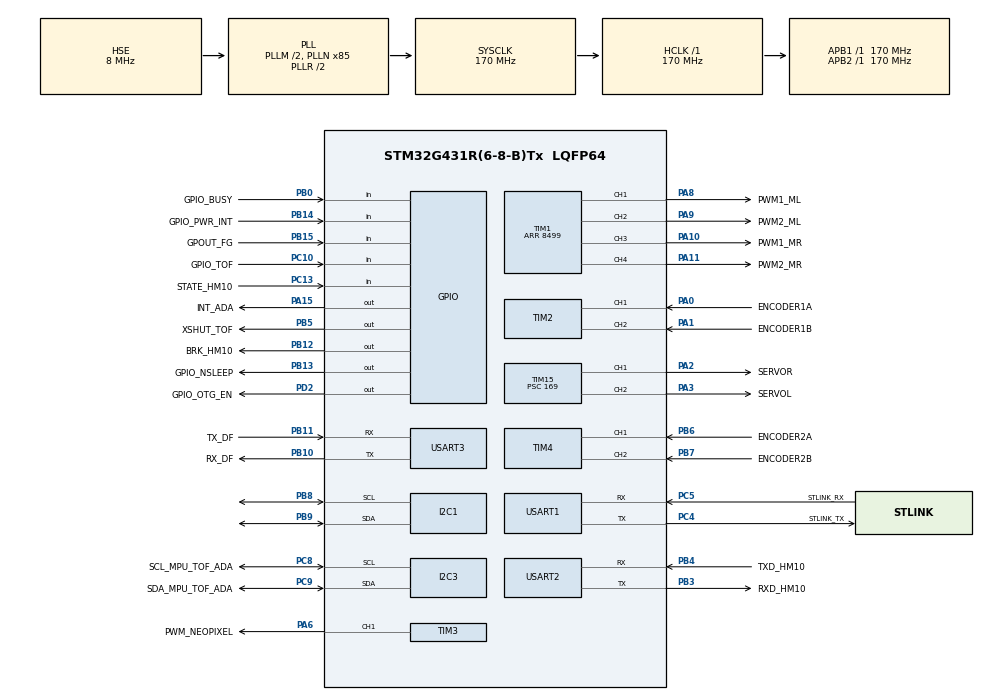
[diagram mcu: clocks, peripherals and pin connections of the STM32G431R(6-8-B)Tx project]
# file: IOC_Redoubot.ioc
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Dma.Request0=TIM3_CH1
Dma.TIM3_CH1.0.Direction=DMA_MEMORY_TO_PERIPH
Dma.TIM3_CH1.0.EventEnable=DISABLE
Dma.TIM3_CH1.0.Instance=DMA1_Channel1
Dma.TIM3_CH1.0.MemDataAlignment=DMA_MDATAALIGN_WORD
Dma.TIM3_CH1.0.MemInc=DMA_MINC_ENABLE
Dma.TIM3_CH1.0.Mode=DMA_NORMAL
Dma.TIM3_CH1.0.PeriphDataAlignment=DMA_PDATAALIGN_HALFWORD
Dma.TIM3_CH1.0.PeriphInc=DMA_PINC_DISABLE
Dma.TIM3_CH1.0.Polarity=HAL_DMAMUX_REQ_GEN_RISING
Dma.TIM3_CH1.0.Priority=DMA_PRIORITY_HIGH
Dma.TIM3_CH1.0.RequestNumber=1
Dma.TIM3_CH1.0.SignalID=NONE
Dma.TIM3_CH1.0.SyncEnable=DISABLE
Dma.TIM3_CH1.0.SyncPolarity=HAL_DMAMUX_SYNC_NO_EVENT
Dma.TIM3_CH1.0.SyncRequestNumber=1
Dma.TIM3_CH1.0.SyncSignalID=NONE
I2C1.Timing=0x40B285C2
I2C3.Timing=0x40B285C2
Mcu.Family=STM32G4
Mcu.Name=STM32G431R(6-8-B)Tx
Mcu.Package=LQFP64
NVIC.DMA1_Channel1_IRQn=true\:0\:0\:false\:false\:true\:false\:true\:true
NVIC.PriorityGroup=NVIC_PRIORITYGROUP_4
PA0.GPIO_Label=ENCODER1A
PA0.Signal=S_TIM2_CH1
PA1.GPIO_Label=ENCODER1B
PA1.Signal=S_TIM2_CH2
PA10.GPIO_Label=PWM1_MR
PA10.Signal=S_TIM1_CH3
PA11.GPIO_Label=PWM2_MR
PA11.Signal=S_TIM1_CH4
PA13.Mode=Serial_Wire
PA13.Signal=SYS_JTMS-SWDIO
PA14.Mode=Serial_Wire
PA14.Signal=SYS_JTCK-SWCLK
PA15.GPIO_Label=INT_ADA
PA15.Signal=GPIO_Output
PA2.GPIO_Label=SERVOR
PA2.Signal=S_TIM15_CH1
PA3.GPIO_Label=SERVOL
PA3.Signal=S_TIM15_CH2
PA6.GPIO_Label=PWM_NEOPIXEL
PA6.GPIO_Speed=GPIO_SPEED_FREQ_VERY_HIGH
PA6.Signal=S_TIM3_CH1
PA8.GPIO_Label=PWM1_ML
PA8.Signal=S_TIM1_CH1
PA9.GPIO_Label=PWM2_ML
PA9.Signal=S_TIM1_CH2
PB0.GPIO_Label=GPIO_BUSY
PB0.Signal=GPIO_Input
PB10.GPIO_Label=RX_DF
PB10.Mode=Asynchronous
PB10.Signal=USART3_TX
PB11.GPIO_Label=TX_DF
PB11.Mode=Asynchronous
PB11.Signal=USART3_RX
PB12.GPIO_Label=BRK_HM10
PB12.Signal=GPIO_Output
PB13.GPIO_Label=GPIO_NSLEEP
PB13.Signal=GPIO_Output
PB14.GPIO_Label=GPIO_PWR_INT
PB14.Signal=GPIO_Input
PB15.GPIO_Label=GPOUT_FG
PB15.Signal=GPIO_Input
PB3.GPIO_Label=RXD_HM10
PB3.Mode=Asynchronous
PB3.Signal=USART2_TX
PB4.GPIO_Label=TXD_HM10
PB4.Mode=Asynchronous
PB4.Signal=USART2_RX
PB5.GPIO_Label=XSHUT_TOF
PB5.Signal=GPIO_Output
PB6.GPIO_Label=ENCODER2A
PB6.Signal=S_TIM4_CH1
PB7.GPIO_Label=ENCODER2B
PB7.Signal=S_TIM4_CH2
PB8-BOOT0.Mode=I2C
PB8-BOOT0.Signal=I2C1_SCL
PB9.Mode=I2C
PB9.Signal=I2C1_SDA
PC10.GPIO_Label=GPIO_TOF
PC10.Signal=GPIO_Input
PC13.GPIO_Label=STATE_HM10
PC13.Signal=GPIO_Input
PC4.GPIO_Label=STLINK_TX
PC4.Mode=Asynchronous
PC4.Signal=USART1_TX
PC5.GPIO_Label=STLINK_RX
PC5.Mode=Asynchronous
PC5.Signal=USART1_RX
PC8.GPIO_Label=SCL_MPU_TOF_ADA
PC8.Mode=I2C
PC8.Signal=I2C3_SCL
PC9.GPIO_Label=SDA_MPU_TOF_ADA
PC9.Mode=I2C
PC9.Signal=I2C3_SDA
PD2.GPIO_Label=GPIO_OTG_EN
PD2.Signal=GPIO_Output
PF0-OSC_IN.Mode=HSE-External-Oscillator
PF0-OSC_IN.Signal=RCC_OSC_IN
PF1-OSC_OUT.Mode=HSE-External-Oscillator
PF1-OSC_OUT.Signal=RCC_OSC_OUT
ProjectManager.HeapSize=0x200
ProjectManager.StackSize=0x400
ProjectManager.TargetToolchain=CMake
RCC.ADC12Freq_Value=170000000
RCC.AHBFreq_Value=170000000
RCC.APB1Freq_Value=170000000
RCC.APB1TimFreq_Value=170000000
RCC.APB2Freq_Value=170000000
RCC.APB2TimFreq_Value=170000000
RCC.CK48CLockSelection=RCC_USBCLKSOURCE_HSI48
RCC.CortexFreq_Value=170000000
RCC.EXTERNAL_CLOCK_VALUE=12288000
RCC.HCLKFreq_Value=170000000
RCC.HSE_VALUE=8000000
RCC.HSI48_VALUE=48000000
RCC.HSI_VALUE=16000000
RCC.LSE_VALUE=32768
RCC.PLLM=RCC_PLLM_DIV2
RCC.PLLN=85
RCC.PLLQ=RCC_PLLQ_DIV4
RCC.PLLSourceVirtual=RCC_PLLSOURCE_HSE
RCC.SYSCLKFreq_VALUE=170000000
RCC.SYSCLKSource=RCC_SYSCLKSOURCE_PLLCLK
RCC.USBFreq_Value=48000000
RCC.VCOOutputFreq_Value=340000000
SH.S_TIM15_CH1.0=TIM15_CH1,PWM Generation1 CH1
SH.S_TIM15_CH2.0=TIM15_CH2,PWM Generation2 CH2
SH.S_TIM1_CH1.0=TIM1_CH1,PWM Generation1 CH1
SH.S_TIM1_CH2.0=TIM1_CH2,PWM Generation2 CH2
SH.S_TIM1_CH3.0=TIM1_CH3,PWM Generation3 CH3
SH.S_TIM1_CH4.0=TIM1_CH4,PWM Generation4 CH4
SH.S_TIM2_CH1.0=TIM2_CH1,Encoder_Interface
SH.S_TIM2_CH2.0=TIM2_CH2,Encoder_Interface
SH.S_TIM3_CH1.0=TIM3_CH1,PWM Generation1 CH1
SH.S_TIM4_CH1.0=TIM4_CH1,Encoder_Interface
SH.S_TIM4_CH2.0=TIM4_CH2,Encoder_Interface
TIM1.AutoReloadPreload=TIM_AUTORELOAD_PRELOAD_ENABLE
TIM1.Channel-PWM\ Generation1\ CH1=TIM_CHANNEL_1
TIM1.Channel-PWM\ Generation2\ CH2=TIM_CHANNEL_2
TIM1.Channel-PWM\ Generation3\ CH3=TIM_CHANNEL_3
TIM1.Channel-PWM\ Generation4\ CH4=TIM_CHANNEL_4
TIM1.PeriodNoDither=8499
TIM15.Channel-PWM\ Generation1\ CH1=TIM_CHANNEL_1
TIM15.Channel-PWM\ Generation2\ CH2=TIM_CHANNEL_2
TIM15.PeriodNoDither=19999
TIM15.Prescaler=169
TIM2.IC1Filter=4
TIM3.Channel-PWM\ Generation1\ CH1=TIM_CHANNEL_1
TIM3.PeriodNoDither=212
TIM3.Prescaler=0
TIM4.IC1Filter=4
USART1.VirtualMode-Asynchronous=VM_ASYNC
USART2.VirtualMode-Asynchronous=VM_ASYNC
USART3.VirtualMode-Asynchronous=VM_ASYNC
VP_SYS_VS_DBSignals.Mode=DisableDeadBatterySignals
board=custom

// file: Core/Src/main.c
/* USER CODE BEGIN Header */
/**
 ******************************************************************************
 * @file           : main.c
 * @brief          : Main program body
 ******************************************************************************
 * @attention
 *
 * Copyright (c) 2026 STMicroelectronics.
 * All rights reserved.
 *
 * This software is licensed under terms that can be found in the LICENSE file
 * in the root directory of this software component.
 * If no LICENSE file comes with this software, it is provided AS-IS.
 *
 ******************************************************************************
 */
/* USER CODE END Header */
#include "main.h"

/* USER CODE BEGIN Includes */
#include "neopixel.h"
/* USER CODE END Includes */

I2C_HandleTypeDef hi2c1;
I2C_HandleTypeDef hi2c3;

TIM_HandleTypeDef htim1;
TIM_HandleTypeDef htim2;
TIM_HandleTypeDef htim3;
TIM_HandleTypeDef htim4;
TIM_HandleTypeDef htim15;
DMA_HandleTypeDef hdma_tim3_ch1;

UART_HandleTypeDef huart1;
UART_HandleTypeDef huart2;
UART_HandleTypeDef huart3;

void SystemClock_Config(void);
static void MX_GPIO_Init(void);
static void MX_DMA_Init(void);
static void MX_I2C1_Init(void);
static void MX_I2C3_Init(void);
static void MX_TIM1_Init(void);
static void MX_TIM2_Init(void);
static void MX_TIM3_Init(void);
static void MX_USART2_UART_Init(void);
static void MX_USART3_UART_Init(void);
static void MX_TIM4_Init(void);
static void MX_TIM15_Init(void);
static void MX_USART1_UART_Init(void);

int main(void)
{

  /* MCU Configuration--------------------------------------------------------*/

  /* Reset of all peripherals, Initializes the Flash interface and the Systick. */
  HAL_Init();

  /* Configure the system clock */
  SystemClock_Config();

  /* Initialize all configured peripherals */
  MX_GPIO_Init();
  MX_DMA_Init();
  MX_I2C1_Init();
  MX_I2C3_Init();
  MX_TIM1_Init();
  MX_TIM2_Init();
  MX_TIM3_Init();
  MX_USART2_UART_Init();
  MX_USART3_UART_Init();
  MX_TIM4_Init();
  MX_TIM15_Init();
  MX_USART1_UART_Init();
  /* USER CODE BEGIN 2 */
	Neo_Init();
	/*
	for (uint16_t i = 0; i < NEO_NUM_LEDS; i++) {
		Neo_SetPixel(i, 0, 0, 40);
		while (Neo_Show() == HAL_BUSY) { }
		HAL_Delay(500);
	}
	*/
  /* USER CODE END 2 */

  /* Infinite loop */
  /* USER CODE BEGIN WHILE */
	while (1)
	{
		Neo_SetAll(255, 0, 0);
		Neo_Show();
		HAL_Delay(1000);
		Neo_SetAll(0, 0, 255);
		Neo_Show();
		HAL_Delay(1000);
    /* USER CODE END WHILE */

	}
}

void SystemClock_Config(void)
{
  RCC_OscInitTypeDef RCC_OscInitStruct = {0};
  RCC_ClkInitTypeDef RCC_ClkInitStruct = {0};

  /** Configure the main internal regulator output voltage
  */
  HAL_PWREx_ControlVoltageScaling(PWR_REGULATOR_VOLTAGE_SCALE1_BOOST);

  /** Initializes the RCC Oscillators according to the specified parameters
  * in the RCC_OscInitTypeDef structure.
  */
  RCC_OscInitStruct.OscillatorType = RCC_OSCILLATORTYPE_HSE;
  RCC_OscInitStruct.HSEState = RCC_HSE_ON;
  RCC_OscInitStruct.PLL.PLLState = RCC_PLL_ON;
  RCC_OscInitStruct.PLL.PLLSource = RCC_PLLSOURCE_HSE;
  RCC_OscInitStruct.PLL.PLLM = RCC_PLLM_DIV2;
  RCC_OscInitStruct.PLL.PLLN = 85;
  RCC_OscInitStruct.PLL.PLLP = RCC_PLLP_DIV2;
  RCC_OscInitStruct.PLL.PLLQ = RCC_PLLQ_DIV4;
  RCC_OscInitStruct.PLL.PLLR = RCC_PLLR_DIV2;
  if (HAL_RCC_OscConfig(&RCC_OscInitStruct) != HAL_OK)
  {
    Error_Handler();
  }

  /** Initializes the CPU, AHB and APB buses clocks
  */
  RCC_ClkInitStruct.ClockType = RCC_CLOCKTYPE_HCLK|RCC_CLOCKTYPE_SYSCLK
                              |RCC_CLOCKTYPE_PCLK1|RCC_CLOCKTYPE_PCLK2;
  RCC_ClkInitStruct.SYSCLKSource = RCC_SYSCLKSOURCE_PLLCLK;
  RCC_ClkInitStruct.AHBCLKDivider = RCC_SYSCLK_DIV1;
  RCC_ClkInitStruct.APB1CLKDivider = RCC_HCLK_DIV1;
  RCC_ClkInitStruct.APB2CLKDivider = RCC_HCLK_DIV1;

  if (HAL_RCC_ClockConfig(&RCC_ClkInitStruct, FLASH_LATENCY_4) != HAL_OK)
  {
    Error_Handler();
  }
}

static void MX_I2C1_Init(void)
{

  hi2c1.Instance = I2C1;
  hi2c1.Init.Timing = 0x40B285C2;
  hi2c1.Init.OwnAddress1 = 0;
  hi2c1.Init.AddressingMode = I2C_ADDRESSINGMODE_7BIT;
  hi2c1.Init.DualAddressMode = I2C_DUALADDRESS_DISABLE;
  hi2c1.Init.OwnAddress2 = 0;
  hi2c1.Init.OwnAddress2Masks = I2C_OA2_NOMASK;
  hi2c1.Init.GeneralCallMode = I2C_GENERALCALL_DISABLE;
  hi2c1.Init.NoStretchMode = I2C_NOSTRETCH_DISABLE;
  if (HAL_I2C_Init(&hi2c1) != HAL_OK)
  {
    Error_Handler();
  }

  /** Configure Analogue filter
  */
  if (HAL_I2CEx_ConfigAnalogFilter(&hi2c1, I2C_ANALOGFILTER_ENABLE) != HAL_OK)
  {
    Error_Handler();
  }

  /** Configure Digital filter
  */
  if (HAL_I2CEx_ConfigDigitalFilter(&hi2c1, 0) != HAL_OK)
  {
    Error_Handler();
  }

}

static void MX_I2C3_Init(void)
{

  hi2c3.Instance = I2C3;
  hi2c3.Init.Timing = 0x40B285C2;
  hi2c3.Init.OwnAddress1 = 0;
  hi2c3.Init.AddressingMode = I2C_ADDRESSINGMODE_7BIT;
  hi2c3.Init.DualAddressMode = I2C_DUALADDRESS_DISABLE;
  hi2c3.Init.OwnAddress2 = 0;
  hi2c3.Init.OwnAddress2Masks = I2C_OA2_NOMASK;
  hi2c3.Init.GeneralCallMode = I2C_GENERALCALL_DISABLE;
  hi2c3.Init.NoStretchMode = I2C_NOSTRETCH_DISABLE;
  if (HAL_I2C_Init(&hi2c3) != HAL_OK)
  {
    Error_Handler();
  }

  /** Configure Analogue filter
  */
  if (HAL_I2CEx_ConfigAnalogFilter(&hi2c3, I2C_ANALOGFILTER_ENABLE) != HAL_OK)
  {
    Error_Handler();
  }

  /** Configure Digital filter
  */
  if (HAL_I2CEx_ConfigDigitalFilter(&hi2c3, 0) != HAL_OK)
  {
    Error_Handler();
  }

}

static void MX_TIM1_Init(void)
{

  TIM_MasterConfigTypeDef sMasterConfig = {0};
  TIM_OC_InitTypeDef sConfigOC = {0};
  TIM_BreakDeadTimeConfigTypeDef sBreakDeadTimeConfig = {0};

  htim1.Instance = TIM1;
  htim1.Init.Prescaler = 0;
  htim1.Init.CounterMode = TIM_COUNTERMODE_UP;
  htim1.Init.Period = 8499;
  htim1.Init.ClockDivision = TIM_CLOCKDIVISION_DIV1;
  htim1.Init.RepetitionCounter = 0;
  htim1.Init.AutoReloadPreload = TIM_AUTORELOAD_PRELOAD_ENABLE;
  if (HAL_TIM_PWM_Init(&htim1) != HAL_OK)
  {
    Error_Handler();
  }
  sMasterConfig.MasterOutputTrigger = TIM_TRGO_RESET;
  sMasterConfig.MasterOutputTrigger2 = TIM_TRGO2_RESET;
  sMasterConfig.MasterSlaveMode = TIM_MASTERSLAVEMODE_DISABLE;
  if (HAL_TIMEx_MasterConfigSynchronization(&htim1, &sMasterConfig) != HAL_OK)
  {
    Error_Handler();
  }
  sConfigOC.OCMode = TIM_OCMODE_PWM1;
  sConfigOC.Pulse = 0;
  sConfigOC.OCPolarity = TIM_OCPOLARITY_HIGH;
  sConfigOC.OCNPolarity = TIM_OCNPOLARITY_HIGH;
  sConfigOC.OCFastMode = TIM_OCFAST_DISABLE;
  sConfigOC.OCIdleState = TIM_OCIDLESTATE_RESET;
  sConfigOC.OCNIdleState = TIM_OCNIDLESTATE_RESET;
  if (HAL_TIM_PWM_ConfigChannel(&htim1, &sConfigOC, TIM_CHANNEL_1) != HAL_OK)
  {
    Error_Handler();
  }
  if (HAL_TIM_PWM_ConfigChannel(&htim1, &sConfigOC, TIM_CHANNEL_2) != HAL_OK)
  {
    Error_Handler();
  }
  if (HAL_TIM_PWM_ConfigChannel(&htim1, &sConfigOC, TIM_CHANNEL_3) != HAL_OK)
  {
    Error_Handler();
  }
  if (HAL_TIM_PWM_ConfigChannel(&htim1, &sConfigOC, TIM_CHANNEL_4) != HAL_OK)
  {
    Error_Handler();
  }
  sBreakDeadTimeConfig.OffStateRunMode = TIM_OSSR_DISABLE;
  sBreakDeadTimeConfig.OffStateIDLEMode = TIM_OSSI_DISABLE;
  sBreakDeadTimeConfig.LockLevel = TIM_LOCKLEVEL_OFF;
  sBreakDeadTimeConfig.DeadTime = 0;
  sBreakDeadTimeConfig.BreakState = TIM_BREAK_DISABLE;
  sBreakDeadTimeConfig.BreakPolarity = TIM_BREAKPOLARITY_HIGH;
  sBreakDeadTimeConfig.BreakFilter = 0;
  sBreakDeadTimeConfig.BreakAFMode = TIM_BREAK_AFMODE_INPUT;
  sBreakDeadTimeConfig.Break2State = TIM_BREAK2_DISABLE;
  sBreakDeadTimeConfig.Break2Polarity = TIM_BREAK2POLARITY_HIGH;
  sBreakDeadTimeConfig.Break2Filter = 0;
  sBreakDeadTimeConfig.Break2AFMode = TIM_BREAK_AFMODE_INPUT;
  sBreakDeadTimeConfig.AutomaticOutput = TIM_AUTOMATICOUTPUT_DISABLE;
  if (HAL_TIMEx_ConfigBreakDeadTime(&htim1, &sBreakDeadTimeConfig) != HAL_OK)
  {
    Error_Handler();
  }
  HAL_TIM_MspPostInit(&htim1);

}

static void MX_TIM2_Init(void)
{

  TIM_Encoder_InitTypeDef sConfig = {0};
  TIM_MasterConfigTypeDef sMasterConfig = {0};

  htim2.Instance = TIM2;
  htim2.Init.Prescaler = 0;
  htim2.Init.CounterMode = TIM_COUNTERMODE_UP;
  htim2.Init.Period = 4294967295;
  htim2.Init.ClockDivision = TIM_CLOCKDIVISION_DIV1;
  htim2.Init.AutoReloadPreload = TIM_AUTORELOAD_PRELOAD_DISABLE;
  sConfig.EncoderMode = TIM_ENCODERMODE_TI1;
  sConfig.IC1Polarity = TIM_ICPOLARITY_RISING;
  sConfig.IC1Selection = TIM_ICSELECTION_DIRECTTI;
  sConfig.IC1Prescaler = TIM_ICPSC_DIV1;
  sConfig.IC1Filter = 4;
  sConfig.IC2Polarity = TIM_ICPOLARITY_RISING;
  sConfig.IC2Selection = TIM_ICSELECTION_DIRECTTI;
  sConfig.IC2Prescaler = TIM_ICPSC_DIV1;
  sConfig.IC2Filter = 0;
  if (HAL_TIM_Encoder_Init(&htim2, &sConfig) != HAL_OK)
  {
    Error_Handler();
  }
  sMasterConfig.MasterOutputTrigger = TIM_TRGO_RESET;
  sMasterConfig.MasterSlaveMode = TIM_MASTERSLAVEMODE_DISABLE;
  if (HAL_TIMEx_MasterConfigSynchronization(&htim2, &sMasterConfig) != HAL_OK)
  {
    Error_Handler();
  }

}

static void MX_TIM3_Init(void)
{

  TIM_MasterConfigTypeDef sMasterConfig = {0};
  TIM_OC_InitTypeDef sConfigOC = {0};

  htim3.Instance = TIM3;
  htim3.Init.Prescaler = 0;
  htim3.Init.CounterMode = TIM_COUNTERMODE_UP;
  htim3.Init.Period = 212;
  htim3.Init.ClockDivision = TIM_CLOCKDIVISION_DIV1;
  htim3.Init.AutoReloadPreload = TIM_AUTORELOAD_PRELOAD_DISABLE;
  if (HAL_TIM_PWM_Init(&htim3) != HAL_OK)
  {
    Error_Handler();
  }
  sMasterConfig.MasterOutputTrigger = TIM_TRGO_RESET;
  sMasterConfig.MasterSlaveMode = TIM_MASTERSLAVEMODE_DISABLE;
  if (HAL_TIMEx_MasterConfigSynchronization(&htim3, &sMasterConfig) != HAL_OK)
  {
    Error_Handler();
  }
  sConfigOC.OCMode = TIM_OCMODE_PWM1;
  sConfigOC.Pulse = 0;
  sConfigOC.OCPolarity = TIM_OCPOLARITY_HIGH;
  sConfigOC.OCFastMode = TIM_OCFAST_DISABLE;
  if (HAL_TIM_PWM_ConfigChannel(&htim3, &sConfigOC, TIM_CHANNEL_1) != HAL_OK)
  {
    Error_Handler();
  }
  HAL_TIM_MspPostInit(&htim3);

}

static void MX_TIM4_Init(void)
{

  TIM_Encoder_InitTypeDef sConfig = {0};
  TIM_MasterConfigTypeDef sMasterConfig = {0};

  htim4.Instance = TIM4;
  htim4.Init.Prescaler = 0;
  htim4.Init.CounterMode = TIM_COUNTERMODE_UP;
  htim4.Init.Period = 65535;
  htim4.Init.ClockDivision = TIM_CLOCKDIVISION_DIV1;
  htim4.Init.AutoReloadPreload = TIM_AUTORELOAD_PRELOAD_DISABLE;
  sConfig.EncoderMode = TIM_ENCODERMODE_TI1;
  sConfig.IC1Polarity = TIM_ICPOLARITY_RISING;
  sConfig.IC1Selection = TIM_ICSELECTION_DIRECTTI;
  sConfig.IC1Prescaler = TIM_ICPSC_DIV1;
  sConfig.IC1Filter = 4;
  sConfig.IC2Polarity = TIM_ICPOLARITY_RISING;
  sConfig.IC2Selection = TIM_ICSELECTION_DIRECTTI;
  sConfig.IC2Prescaler = TIM_ICPSC_DIV1;
  sConfig.IC2Filter = 0;
  if (HAL_TIM_Encoder_Init(&htim4, &sConfig) != HAL_OK)
  {
    Error_Handler();
  }
  sMasterConfig.MasterOutputTrigger = TIM_TRGO_RESET;
  sMasterConfig.MasterSlaveMode = TIM_MASTERSLAVEMODE_DISABLE;
  if (HAL_TIMEx_MasterConfigSynchronization(&htim4, &sMasterConfig) != HAL_OK)
  {
    Error_Handler();
  }

}

static void MX_TIM15_Init(void)
{

  TIM_MasterConfigTypeDef sMasterConfig = {0};
  TIM_OC_InitTypeDef sConfigOC = {0};
  TIM_BreakDeadTimeConfigTypeDef sBreakDeadTimeConfig = {0};

  htim15.Instance = TIM15;
  htim15.Init.Prescaler = 169;
  htim15.Init.CounterMode = TIM_COUNTERMODE_UP;
  htim15.Init.Period = 19999;
  htim15.Init.ClockDivision = TIM_CLOCKDIVISION_DIV1;
  htim15.Init.RepetitionCounter = 0;
  htim15.Init.AutoReloadPreload = TIM_AUTORELOAD_PRELOAD_DISABLE;
  if (HAL_TIM_PWM_Init(&htim15) != HAL_OK)
  {
    Error_Handler();
  }
  sMasterConfig.MasterOutputTrigger = TIM_TRGO_RESET;
  sMasterConfig.MasterSlaveMode = TIM_MASTERSLAVEMODE_DISABLE;
  if (HAL_TIMEx_MasterConfigSynchronization(&htim15, &sMasterConfig) != HAL_OK)
  {
    Error_Handler();
  }
  sConfigOC.OCMode = TIM_OCMODE_PWM1;
  sConfigOC.Pulse = 0;
  sConfigOC.OCPolarity = TIM_OCPOLARITY_HIGH;
  sConfigOC.OCNPolarity = TIM_OCNPOLARITY_HIGH;
  sConfigOC.OCFastMode = TIM_OCFAST_DISABLE;
  sConfigOC.OCIdleState = TIM_OCIDLESTATE_RESET;
  sConfigOC.OCNIdleState = TIM_OCNIDLESTATE_RESET;
  if (HAL_TIM_PWM_ConfigChannel(&htim15, &sConfigOC, TIM_CHANNEL_1) != HAL_OK)
  {
    Error_Handler();
  }
  if (HAL_TIM_PWM_ConfigChannel(&htim15, &sConfigOC, TIM_CHANNEL_2) != HAL_OK)
  {
    Error_Handler();
  }
  sBreakDeadTimeConfig.OffStateRunMode = TIM_OSSR_DISABLE;
  sBreakDeadTimeConfig.OffStateIDLEMode = TIM_OSSI_DISABLE;
  sBreakDeadTimeConfig.LockLevel = TIM_LOCKLEVEL_OFF;
  sBreakDeadTimeConfig.DeadTime = 0;
  sBreakDeadTimeConfig.BreakState = TIM_BREAK_DISABLE;
  sBreakDeadTimeConfig.BreakPolarity = TIM_BREAKPOLARITY_HIGH;
  sBreakDeadTimeConfig.BreakFilter = 0;
  sBreakDeadTimeConfig.AutomaticOutput = TIM_AUTOMATICOUTPUT_DISABLE;
  if (HAL_TIMEx_ConfigBreakDeadTime(&htim15, &sBreakDeadTimeConfig) != HAL_OK)
  {
    Error_Handler();
  }
  HAL_TIM_MspPostInit(&htim15);

}

static void MX_USART1_UART_Init(void)
{

  huart1.Instance = USART1;
  huart1.Init.BaudRate = 115200;
  huart1.Init.WordLength = UART_WORDLENGTH_8B;
  huart1.Init.StopBits = UART_STOPBITS_1;
  huart1.Init.Parity = UART_PARITY_NONE;
  huart1.Init.Mode = UART_MODE_TX_RX;
  huart1.Init.HwFlowCtl = UART_HWCONTROL_NONE;
  huart1.Init.OverSampling = UART_OVERSAMPLING_16;
  huart1.Init.OneBitSampling = UART_ONE_BIT_SAMPLE_DISABLE;
  huart1.Init.ClockPrescaler = UART_PRESCALER_DIV1;
  huart1.AdvancedInit.AdvFeatureInit = UART_ADVFEATURE_NO_INIT;
  if (HAL_UART_Init(&huart1) != HAL_OK)
  {
    Error_Handler();
  }
  if (HAL_UARTEx_SetTxFifoThreshold(&huart1, UART_TXFIFO_THRESHOLD_1_8) != HAL_OK)
  {
    Error_Handler();
  }
  if (HAL_UARTEx_SetRxFifoThreshold(&huart1, UART_RXFIFO_THRESHOLD_1_8) != HAL_OK)
  {
    Error_Handler();
  }
  if (HAL_UARTEx_DisableFifoMode(&huart1) != HAL_OK)
  {
    Error_Handler();
  }

}

static void MX_USART2_UART_Init(void)
{

  huart2.Instance = USART2;
  huart2.Init.BaudRate = 115200;
  huart2.Init.WordLength = UART_WORDLENGTH_8B;
  huart2.Init.StopBits = UART_STOPBITS_1;
  huart2.Init.Parity = UART_PARITY_NONE;
  huart2.Init.Mode = UART_MODE_TX_RX;
  huart2.Init.HwFlowCtl = UART_HWCONTROL_NONE;
  huart2.Init.OverSampling = UART_OVERSAMPLING_16;
  huart2.Init.OneBitSampling = UART_ONE_BIT_SAMPLE_DISABLE;
  huart2.Init.ClockPrescaler = UART_PRESCALER_DIV1;
  huart2.AdvancedInit.AdvFeatureInit = UART_ADVFEATURE_NO_INIT;
  if (HAL_UART_Init(&huart2) != HAL_OK)
  {
    Error_Handler();
  }
  if (HAL_UARTEx_SetTxFifoThreshold(&huart2, UART_TXFIFO_THRESHOLD_1_8) != HAL_OK)
  {
    Error_Handler();
  }
  if (HAL_UARTEx_SetRxFifoThreshold(&huart2, UART_RXFIFO_THRESHOLD_1_8) != HAL_OK)
  {
    Error_Handler();
  }
  if (HAL_UARTEx_DisableFifoMode(&huart2) != HAL_OK)
  {
    Error_Handler();
  }

}

static void MX_USART3_UART_Init(void)
{

  huart3.Instance = USART3;
  huart3.Init.BaudRate = 115200;
  huart3.Init.WordLength = UART_WORDLENGTH_8B;
  huart3.Init.StopBits = UART_STOPBITS_1;
  huart3.Init.Parity = UART_PARITY_NONE;
  huart3.Init.Mode = UART_MODE_TX_RX;
  huart3.Init.HwFlowCtl = UART_HWCONTROL_NONE;
  huart3.Init.OverSampling = UART_OVERSAMPLING_16;
  huart3.Init.OneBitSampling = UART_ONE_BIT_SAMPLE_DISABLE;
  huart3.Init.ClockPrescaler = UART_PRESCALER_DIV1;
  huart3.AdvancedInit.AdvFeatureInit = UART_ADVFEATURE_NO_INIT;
  if (HAL_UART_Init(&huart3) != HAL_OK)
  {
    Error_Handler();
  }
  if (HAL_UARTEx_SetTxFifoThreshold(&huart3, UART_TXFIFO_THRESHOLD_1_8) != HAL_OK)
  {
    Error_Handler();
  }
  if (HAL_UARTEx_SetRxFifoThreshold(&huart3, UART_RXFIFO_THRESHOLD_1_8) != HAL_OK)
  {
    Error_Handler();
  }
  if (HAL_UARTEx_DisableFifoMode(&huart3) != HAL_OK)
  {
    Error_Handler();
  }

}

static void MX_DMA_Init(void)
{

  /* DMA controller clock enable */
  __HAL_RCC_DMAMUX1_CLK_ENABLE();
  __HAL_RCC_DMA1_CLK_ENABLE();

  /* DMA interrupt init */
  /* DMA1_Channel1_IRQn interrupt configuration */
  HAL_NVIC_SetPriority(DMA1_Channel1_IRQn, 0, 0);
  HAL_NVIC_EnableIRQ(DMA1_Channel1_IRQn);

}

static void MX_GPIO_Init(void)
{
  GPIO_InitTypeDef GPIO_InitStruct = {0};

  /* GPIO Ports Clock Enable */
  __HAL_RCC_GPIOC_CLK_ENABLE();
  __HAL_RCC_GPIOF_CLK_ENABLE();
  __HAL_RCC_GPIOA_CLK_ENABLE();
  __HAL_RCC_GPIOB_CLK_ENABLE();
  __HAL_RCC_GPIOD_CLK_ENABLE();

  /*Configure GPIO pin Output Level */
  HAL_GPIO_WritePin(GPIOB, BRK_HM10_Pin|GPIO_NSLEEP_Pin|XSHUT_TOF_Pin, GPIO_PIN_RESET);

  /*Configure GPIO pin Output Level */
  HAL_GPIO_WritePin(INT_ADA_GPIO_Port, INT_ADA_Pin, GPIO_PIN_RESET);

  /*Configure GPIO pin Output Level */
  HAL_GPIO_WritePin(GPIO_OTG_EN_GPIO_Port, GPIO_OTG_EN_Pin, GPIO_PIN_RESET);

  /*Configure GPIO pins : STATE_HM10_Pin GPIO_TOF_Pin */
  GPIO_InitStruct.Pin = STATE_HM10_Pin|GPIO_TOF_Pin;
  GPIO_InitStruct.Mode = GPIO_MODE_INPUT;
  GPIO_InitStruct.Pull = GPIO_NOPULL;
  HAL_GPIO_Init(GPIOC, &GPIO_InitStruct);

  /*Configure GPIO pins : GPIO_BUSY_Pin GPIO_PWR_INT_Pin GPOUT_FG_Pin */
  GPIO_InitStruct.Pin = GPIO_BUSY_Pin|GPIO_PWR_INT_Pin|GPOUT_FG_Pin;
  GPIO_InitStruct.Mode = GPIO_MODE_INPUT;
  GPIO_InitStruct.Pull = GPIO_NOPULL;
  HAL_GPIO_Init(GPIOB, &GPIO_InitStruct);

  /*Configure GPIO pins : BRK_HM10_Pin GPIO_NSLEEP_Pin XSHUT_TOF_Pin */
  GPIO_InitStruct.Pin = BRK_HM10_Pin|GPIO_NSLEEP_Pin|XSHUT_TOF_Pin;
  GPIO_InitStruct.Mode = GPIO_MODE_OUTPUT_PP;
  GPIO_InitStruct.Pull = GPIO_NOPULL;
  GPIO_InitStruct.Speed = GPIO_SPEED_FREQ_LOW;
  HAL_GPIO_Init(GPIOB, &GPIO_InitStruct);

  /*Configure GPIO pin : INT_ADA_Pin */
  GPIO_InitStruct.Pin = INT_ADA_Pin;
  GPIO_InitStruct.Mode = GPIO_MODE_OUTPUT_PP;
  GPIO_InitStruct.Pull = GPIO_NOPULL;
  GPIO_InitStruct.Speed = GPIO_SPEED_FREQ_LOW;
  HAL_GPIO_Init(INT_ADA_GPIO_Port, &GPIO_InitStruct);

  /*Configure GPIO pin : GPIO_OTG_EN_Pin */
  GPIO_InitStruct.Pin = GPIO_OTG_EN_Pin;
  GPIO_InitStruct.Mode = GPIO_MODE_OUTPUT_PP;
  GPIO_InitStruct.Pull = GPIO_NOPULL;
  GPIO_InitStruct.Speed = GPIO_SPEED_FREQ_LOW;
  HAL_GPIO_Init(GPIO_OTG_EN_GPIO_Port, &GPIO_InitStruct);

}

void Error_Handler(void)
{
	__disable_irq();
	while (1)
	{
	}
}
